VERSION "HIPBNYYYYYYYYYYYYYYYYYYYYYYYYYYYYYYYYYYYYY/4/%%%/4/'%**4YYY///"

NS_ :

BS_:

BU_:

BO_ 2566890272 DoubleMessage: 8 Vector__XXX
 SG_ LittleEndianDouble : 0|64@1- (1,0) [0|0] "" Vector__XXX
 SG_ BigEndianDouble : 7|64@0- (1,0) [0|0] "" Vector__XXX

BO_ 2566906689 FloatMessage: 8 Vector__XXX
 SG_ LittleEndianFloat : 0|32@1- (1,0) [0|0] "" Vector__XXX
 SG_ BigEndianFloat : 39|32@0- (1,0) [0|0] "" Vector__XXX

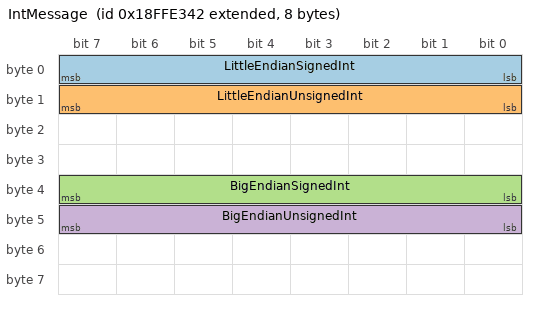
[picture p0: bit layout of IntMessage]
BO_ 2566906690 IntMessage: 8 Vector__XXX
 SG_ LittleEndianSignedInt : 0|8@1- (1,0) [0|0] "" Vector__XXX
 SG_ LittleEndianUnsignedInt : 8|8@1+ (1,0) [0|0] "" Vector__XXX
 SG_ BigEndianSignedInt : 39|8@0- (1,0) [0|0] "" Vector__XXX
 SG_ BigEndianUnsignedInt : 47|8@0+ (1,0) [0|0] "" Vector__XXX

SIG_VALTYPE_ 2566906690 LittleEndianSignedInt : 0;
SIG_VALTYPE_ 2566906690 LittleEndianUnsignedInt : 0;
SIG_VALTYPE_ 2566906690 BigEndianSignedInt : 0;
SIG_VALTYPE_ 2566906690 BigEndianUnsignedInt : 0;
SIG_VALTYPE_ 2566906689 LittleEndianFloat : 1;
SIG_VALTYPE_ 2566906689 BigEndianFloat : 1;
SIG_VALTYPE_ 2566890272 LittleEndianDouble : 2;
SIG_VALTYPE_ 2566890272 BigEndianDouble : 2;
